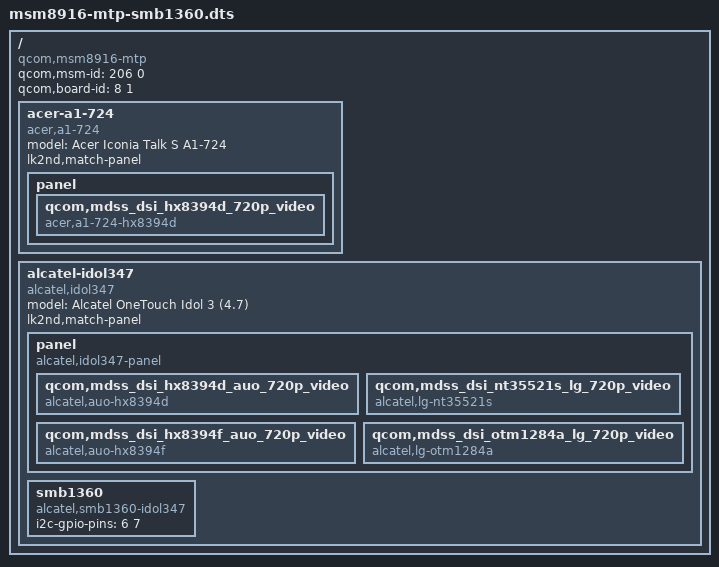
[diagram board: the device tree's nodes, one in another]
// SPDX-License-Identifier: GPL-2.0-only

/dts-v1/;

#include <skeleton.dtsi>

/ {
	compatible = "qcom,msm8916-mtp", "qcom,msm8916";
	qcom,msm-id = <206 0>;
	qcom,board-id = <8 1>;

	/*
	* To get a working build for acer-a1-724, comment out all lines
	* except $(LOCAL_DIR)/msm8916-mtp-smb1360.dtb in rules.mk in this
	* directory.
	* a1-724 does not work with all dtbs enabled; the bootloader gets
	* upset and goes into the phone's fastboot.
	*/
	acer-a1-724 {
		model = "Acer Iconia Talk S A1-724";
		compatible = "acer,a1-724", "qcom,msm8916", "lk2nd,device";
		lk2nd,match-panel;

		panel {
			qcom,mdss_dsi_hx8394d_720p_video {
				compatible = "acer,a1-724-hx8394d";
			};
		};
	};

	alcatel-idol347 {
		model = "Alcatel OneTouch Idol 3 (4.7)";
		compatible = "alcatel,idol347", "qcom,msm8916", "lk2nd,device";
		lk2nd,match-panel;

		panel {
			compatible = "alcatel,idol347-panel";

			qcom,mdss_dsi_hx8394d_auo_720p_video {
				compatible = "alcatel,auo-hx8394d";
			};
			qcom,mdss_dsi_hx8394f_auo_720p_video {
				compatible = "alcatel,auo-hx8394f";
			};
			qcom,mdss_dsi_nt35521s_lg_720p_video {
				compatible = "alcatel,lg-nt35521s";
			};
			qcom,mdss_dsi_otm1284a_lg_720p_video {
				compatible = "alcatel,lg-otm1284a";
			};
		};

		smb1360 {
			compatible = "alcatel,smb1360-idol347", "qcom,smb1360";
			i2c-gpio-pins = <6 7>;
		};
	};
};
